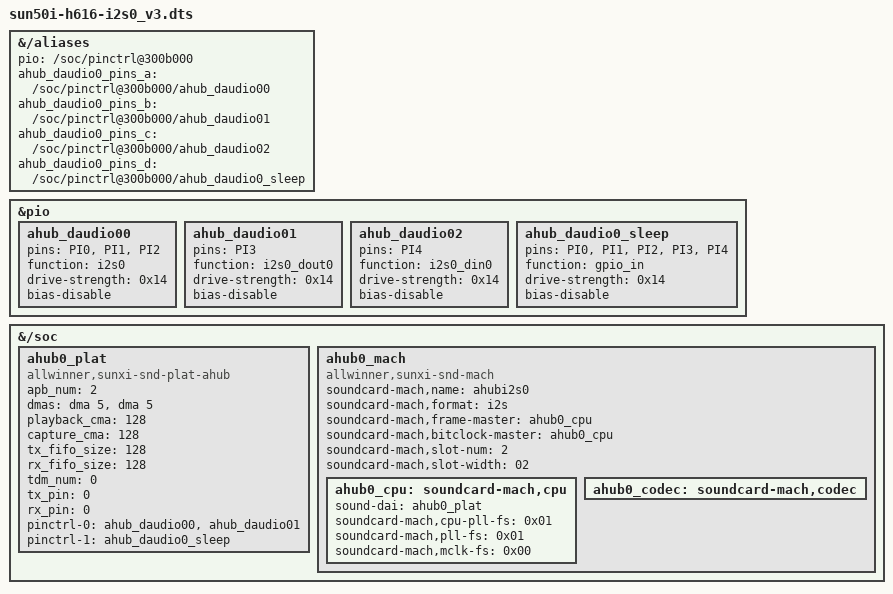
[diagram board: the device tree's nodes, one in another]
/dts-v1/;
/plugin/;

&{/aliases} {
	pio = "/soc/pinctrl@300b000";
	ahub_daudio0_pins_a = "/soc/pinctrl@300b000/ahub_daudio00";
	ahub_daudio0_pins_b = "/soc/pinctrl@300b000/ahub_daudio01";
	ahub_daudio0_pins_c = "/soc/pinctrl@300b000/ahub_daudio02";
	ahub_daudio0_pins_d = "/soc/pinctrl@300b000/ahub_daudio0_sleep";
	};

&pio {
		ahub_daudio00: ahub_daudio00 {
			pins = "PI0", "PI1", "PI2";
			function = "i2s0";
			drive-strength = <0x14>;
			bias-disable;
//			phandle = <0xb3>;
						};
		ahub_daudio01: ahub_daudio01 {
			pins = "PI3";
			function = "i2s0_dout0";
			drive-strength = <0x14>;
			bias-disable;
//			phandle = <0xb1>;
						};
		ahub_daudio02: ahub_daudio02  {
			pins = "PI4";
			function = "i2s0_din0";
			drive-strength = <0x14>;
			bias-disable;
//			phandle = <0xb2>;
						};
		ahub_daudio0_sleep: ahub_daudio0_sleep  {
			pins = "PI0", "PI1", "PI2", "PI3", "PI4";
			function = "gpio_in";
			drive-strength = <0x14>;
			bias-disable;
//			phandle = <0xb0>;
						};
};

&{/soc}  {
	ahub0_plat: ahub0_plat {
		#sound-dai-cells = <0>;
		compatible	= "allwinner,sunxi-snd-plat-ahub";
		apb_num		= <2>;	/* for dma port 5 */
		dmas		= <&dma 5>, <&dma 5>;
		dma-names	= "tx", "rx";
		playback_cma	= <128>;
		capture_cma	= <128>;
		tx_fifo_size	= <128>;
		rx_fifo_size	= <128>;

		tdm_num		= <0>;
		tx_pin		= <0>;
		rx_pin		= <0>;
		status		= "okay";

		pinctrl-names = "default", "sleep";
		pinctrl-0 = <&ahub_daudio00>, <&ahub_daudio01>;
		pinctrl-1 = <&ahub_daudio0_sleep>;

		};
	ahub0_mach: ahub0_mach {
		compatible = "allwinner,sunxi-snd-mach";
		soundcard-mach,name = "ahubi2s0";
		soundcard-mach,format		= "i2s";
		soundcard-mach,frame-master	= <&ahub0_cpu>;
		soundcard-mach,bitclock-master	= <&ahub0_cpu>;
		/* soundcard-mach,frame-inversion; */
		/* soundcard-mach,bitclock-inversion; */
		soundcard-mach,slot-num		= <2>;
		soundcard-mach,slot-width	= <02>;
		status = "okay";
		ahub0_cpu: soundcard-mach,cpu {
			sound-dai = <&ahub0_plat>;
			soundcard-mach,cpu-pll-fs = <0x01>;
			soundcard-mach,pll-fs	= <0x01>;
			soundcard-mach,mclk-fs	= <0x00>;
						};

			ahub0_codec: soundcard-mach,codec {
							};
				};
};
